# PIC32CX2051BZ62132 register map
Vendor: Microchip Technology; Series: PIC32CXBZ62; File version: 0
CPU: CM4 r0p1, little endian, MPU, FPU, 3 interrupt priority bits, 58 interrupts
Registers are 32-bit, read-write, reset 0x0 unless marked. A register's access mark holds for its fields unless they carry their own. Offsets are from the block's base; [hi:lo] are bit positions; lines under a group give offsets from that group; {n}, {i} and the like mark numbered series; 'fields as' and 'values as' point back to an identical list.

## DMAC — Direct Memory Access Controller
Base 0x41004000
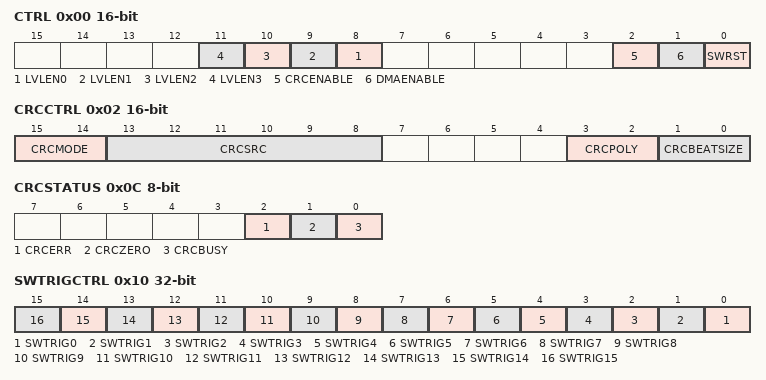
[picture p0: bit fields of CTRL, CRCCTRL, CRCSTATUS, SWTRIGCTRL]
0x00 CTRL 16-bit — Control
  [n+8] LVLEN{n} (n=0..3) — Priority Level {n} Enable
  [2] CRCENABLE
  [1] DMAENABLE
  [0] SWRST — Software Reset
0x02 CRCCTRL 16-bit — CRC Control
  [15:14] CRCMODE — CRC Operating Mode
    0=DEFAULT (Default operating mode); 2=CRCMON (Memory CRC monitor operating mode); 3=CRCGEN (Memory CRC generation operating mode)
  [13:8] CRCSRC — CRC Input Source
    0=DISABLE (CRC Disabled); 1=IO (I/O interface)
  [3:2] CRCPOLY — CRC Polynomial Type
    0=CRC16 (CRC-16 (CRC-CCITT)); 1=CRC32 (CRC32 (IEEE 802.3))
  [1:0] CRCBEATSIZE
    0=BYTE (8-bit bus transfer); 1=HWORD (16-bit bus transfer); 2=WORD (32-bit bus transfer)
0x04 CRCDATAIN — CRC Data Input
0x08 CRCCHKSUM — CRC Checksum
0x0C CRCSTATUS 8-bit
  [2] CRCERR — CRC Error
  [1] CRCZERO
  [0] CRCBUSY — CRC Module Busy
0x0D DBGCTRL 8-bit — Debug Control
  [0] DBGRUN — Debug Run
0x10 SWTRIGCTRL — Software Trigger Control
  [n] SWTRIG{n} (n=0..15) — Channel {n} Software Trigger
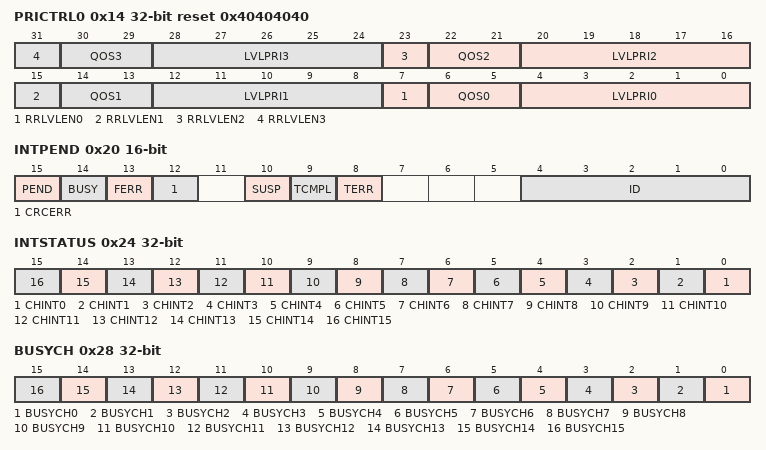
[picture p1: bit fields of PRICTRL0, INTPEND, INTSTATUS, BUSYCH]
0x14 PRICTRL0 reset 0x40404040 — Priority Control 0
  [8n+7] RRLVLEN{n} (n=0..3) — Level {n} Round-Robin Scheduling Enable
  [8n+6:8n+5] QOS{n} (n=0..3) — Level {n} Quality of Service
    0=REGULAR (Regular delivery); 1=SHORTAGE (Bandwidth shortage); 2=SENSITIVE (Latency sensitive); 3=CRITICAL (Latency critical)
  [8n+4:8n] LVLPRI{n} (n=0..3) — Level {n} Channel Priority Number
0x20 INTPEND 16-bit — Interrupt Pending
  [15] PEND — Pending
  [14] BUSY
  [13] FERR — Fetch Error
  [12] CRCERR — CRC Error
  [10] SUSP — Channel Suspend
  [9] TCMPL — Transfer Complete
  [8] TERR — Transfer Error
  [4:0] ID — Channel ID
0x24 INTSTATUS ro — Interrupt Status
  [n] CHINT{n} (n=0..15) — Channel {n} Pending Interrupt
0x28 BUSYCH ro — Busy Channels
  [n] BUSYCH{n} (n=0..15) — Busy Channel {n}
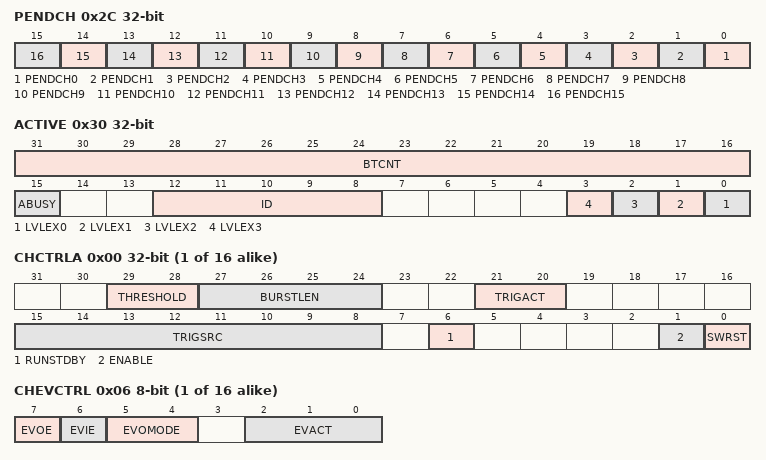
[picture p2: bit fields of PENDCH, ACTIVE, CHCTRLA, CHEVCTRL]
0x2C PENDCH ro — Pending Channels
  [n] PENDCH{n} (n=0..15) — Pending Channel {n}
0x30 ACTIVE ro — Active Channel and Levels
  [31:16] BTCNT — Active Channel Block Transfer Count
  [15] ABUSY — Active Channel Busy
  [12:8] ID — Active Channel ID
  [n] LVLEX{n} (n=0..3) — Level {n} Channel Trigger Request Executing
0x34 BASEADDR — Descriptor Memory Section Base Address
  [31:0] BASEADDR — Descriptor Memory Base Address
0x38 WRBADDR — Write-Back Memory Section Base Address
  [31:0] WRBADDR — Write-Back Memory Base Address
{0x40+0x10*i} CHANNEL[{i}] (i=0..15) group
  0x00 CHCTRLA — Channel n Control A
    [29:28] THRESHOLD — FIFO Threshold
      0=1BEAT (Destination write starts after each beat source address read); 1=2BEATS (Destination write starts after 2-beats source address read); 2=4BEATS (Destination write starts after 4-beats source address read); 3=8BEATS (Destination write starts after 8-beats source address read)
    [27:24] BURSTLEN — Burst Length
      0=SINGLE (Single-beat burst length); {v}={v+1}BEAT ({v+1}-beats burst length) (v=1..15)
    [21:20] TRIGACT — Trigger Action
      0=BLOCK (One trigger required for each block transfer); 2=BURST (One trigger required for each burst transfer); 3=TRANSACTION (One trigger required for each transaction)
    [15:8] TRIGSRC — Trigger Source
      0=DISABLE (Only software/event triggers); 1=RTC_DMAC_ID_TIMESTAMP (Trigger source is RTC); 2=DSU_DMAC_ID_DCC0 (Trigger source is DSU DCC0); 3=DSU_DMAC_ID_DCC1 (Trigger source is DSU DCC1); 4=SERCOM0_DMAC_ID_RX (Trigger source is SERCOM0 RX); 5=SERCOM0_DMAC_ID_TX (Trigger source is SERCOM0 TX); 6=SERCOM1_DMAC_ID_RX (Trigger source is SERCOM1 RX); 7=SERCOM1_DMAC_ID_TX (Trigger source is SERCOM1 TX); 8=SERCOM2_DMAC_ID_RX (Trigger source is SERCOM2 RX); 9=SERCOM2_DMAC_ID_TX (Trigger source is SERCOM2 TX); 10=SERCOM3_DMAC_ID_RX (Trigger source is SERCOM3 RX); 11=SERCOM3_DMAC_ID_TX (Trigger source is SERCOM3 TX); 12=SERCOM4_DMAC_ID_RX (Trigger source is SERCOM4 RX); 13=SERCOM4_DMAC_ID_TX (Trigger source is SERCOM4 TX); 14=SERCOM5_DMAC_ID_RX (Trigger source is SERCOM5 RX); 15=SERCOM5_DMAC_ID_TX (Trigger source is SERCOM5 TX); 16=SERCOM6_DMAC_ID_RX (Trigger source is SERCOM6 RX); 17=SERCOM6_DMAC_ID_TX (Trigger source is SERCOM6 TX); 18=TCC0_DMAC_ID_OVF (Trigger source is TCC0 OVF); {v}=TCC0_DMAC_ID_MC_{v-19} (Trigger source is TCC0 MC{v-19}) (v=19..24); 25=TCC1_DMAC_ID_OVF (Trigger source is TCC1 OVF); {v}=TCC1_DMAC_ID_MC_{v-26} (Trigger source is TCC1 MC{v-26}) (v=26..31); 32=TCC2_DMAC_ID_OVF (Trigger source is TCC2 OVF); 33=TCC2_DMAC_ID_MC_0 (Trigger source is TCC2 MC0); 34=TCC2_DMAC_ID_MC_1 (Trigger source is TCC2 MC1); 35=TC0_DMAC_ID_OVF (Trigger source is TCO OVF); 36=TC0_DMAC_ID_MC_0 (Trigger source is TC0 MC0); 37=TC0_DMAC_ID_MC_1 (Trigger source is TC0 MC1); 38=TC1_DMAC_ID_OVF (Trigger source is TC1 OVF); 39=TC1_DMAC_ID_MC_0 (Trigger source is TC1 MC0); 40=TC1_DMAC_ID_MC_1 (Trigger source is TC1 MC1); 41=TC2_DMAC_ID_OVF (Trigger source is TC2 OVF); 42=TC2_DMAC_ID_MC_0 (Trigger source is TC2 MC0); 43=TC2_DMAC_ID_MC_1 (Trigger source is TC2 MC1); 44=TC3_DMAC_ID_OVF (Trigger source is TC3 OVF); 45=TC3_DMAC_ID_MC_0 (Trigger source is TC3 MC0); 46=TC3_DMAC_ID_MC_1 (Trigger source is TC3 MC1); 47=TC4_DMAC_ID_OVF (Trigger source is TC4 OVF); 48=TC4_DMAC_ID_MC_0 (Trigger source is TC4 MC0); 49=TC4_DMAC_ID_MC_1 (Trigger source is TC4 MC1); 50=TC5_DMAC_ID_OVF (Trigger source is TC5 OVF); 51=TC5_DMAC_ID_MC_0 (Trigger source is TC5 MC0); 52=TC5_DMAC_ID_MC_1 (Trigger source is TC5 MC1); 53=TC6_DMAC_ID_OVF (Trigger source is TC6 OVF); 54=TC6_DMAC_ID_MC_0 (Trigger source is TC6 MC0); 55=TC6_DMAC_ID_MC_1 (Trigger source is TC6 MC1); 56=TC7_DMAC_ID_OVF (Trigger source is TC7 OVF); 57=TC7_DMAC_ID_MC_0 (Trigger source is TC7 MC0); 58=TC7_DMAC_ID_MC_1 (Trigger source is TC7 MC1); 59=TC8_DMAC_ID_OVF (Trigger source is TC8 OVF); 60=TC8_DMAC_ID_MC_0 (Trigger source is TC8 MC0); 61=TC8_DMAC_ID_MC_1 (Trigger source is TC8 MC1); 62=TC9_DMAC_ID_OVF (Trigger source is TC9 OVF); 63=TC9_DMAC_ID_MC_0 (Trigger source is TC9 MC0); 64=TC9_DMAC_ID_MC_1 (Trigger source is TC9 MC1); 65=QSPI_DMAC_ID_RX (Trigger source is QSPI RX); 66=QSPI_DMAC_ID_TX (Trigger source is QSPI TX)
    [6] RUNSTDBY — Channel Run in Standby
    [1] ENABLE — Channel Enable
    [0] SWRST — Channel Software Reset
  0x04 CHCTRLB 8-bit — Channel n Control B
    [1:0] CMD — Software Command
      0=NOACT (No action); 1=SUSPEND (Channel suspend operation); 2=RESUME (Channel resume operation)
  0x05 CHPRILVL 8-bit — Channel n Priority Level
    [1:0] PRILVL — Channel Priority Level
      0=LVL0 (Channel Priority Level 0 (Lowest Level)); 1=LVL1 (Channel Priority Level 1); 2=LVL2 (Channel Priority Level 2); 3=LVL3 (Channel Priority Level 3 (Highest Level))
  0x06 CHEVCTRL 8-bit — Channel n Event Control
    [7] EVOE — Channel Event Output Enable
    [6] EVIE — Channel Event Input Enable
    [5:4] EVOMODE — Channel Event Output Mode
      0=DEFAULT (Block event output selection. Refer to BTCTRL.EVOSEL for available selections.); 1=TRIGACT (Ongoing trigger action)
    [2:0] EVACT — Channel Event Input Action
      0=NOACT (No action); 1=TRIG (Transfer and periodic transfer trigger); 2=CTRIG (Conditional transfer trigger); 3=CBLOCK (Conditional block transfer); 4=SUSPEND (Channel suspend operation); 5=RESUME (Channel resume operation); 6=SSKIP (Skip next block suspend action); 7=INCPRI (Increase priority)
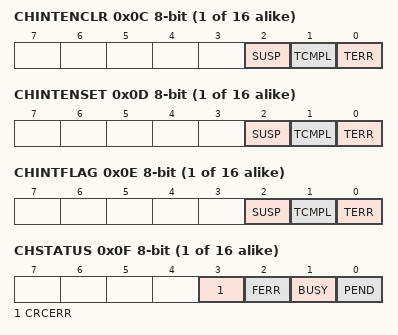
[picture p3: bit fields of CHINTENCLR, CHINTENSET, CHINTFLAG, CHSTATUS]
  0x0C CHINTENCLR 8-bit write-1-clears — Channel n Interrupt Enable Clear
    [2] SUSP — Channel Suspend Interrupt Enable
    [1] TCMPL — Channel Transfer Complete Interrupt Enable
    [0] TERR — Channel Transfer Error Interrupt Enable
  0x0D CHINTENSET 8-bit write-1-sets — Channel n Interrupt Enable Set
    fields as CHANNEL[0].CHINTENCLR
  0x0E CHINTFLAG 8-bit write-1-clears — Channel n Interrupt Flag Status and Clear
    [2] SUSP — Channel Suspend
    [1] TCMPL — Channel Transfer Complete
    [0] TERR — Channel Transfer Error
  0x0F CHSTATUS 8-bit — Channel n Status
    [3] CRCERR — Channel CRC Error
    [2] FERR — Channel Fetch Error
    [1] BUSY — Channel Busy
    [0] PEND — Channel Pending
